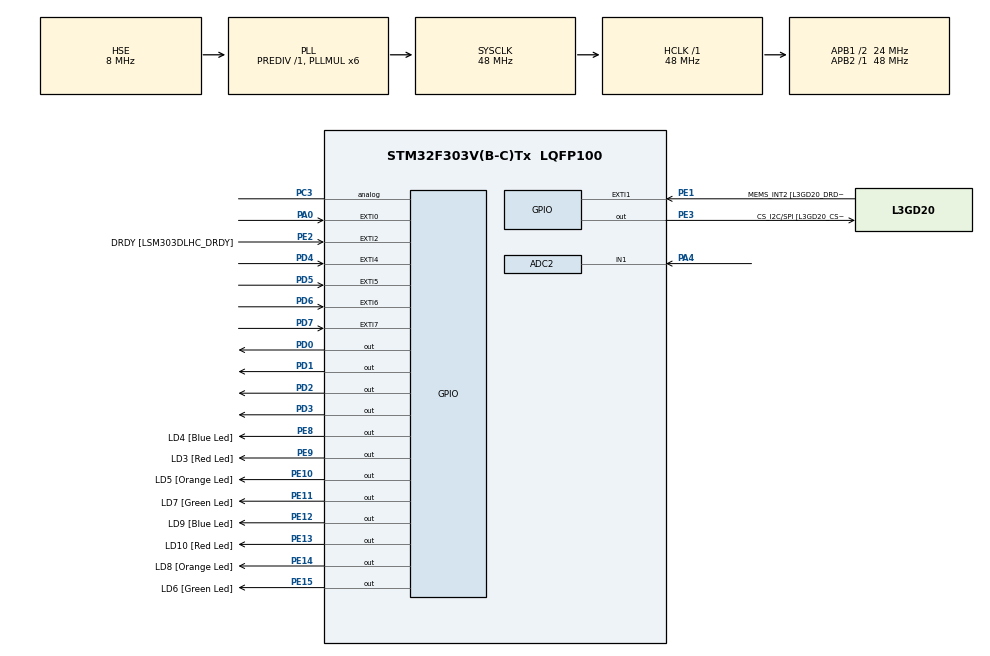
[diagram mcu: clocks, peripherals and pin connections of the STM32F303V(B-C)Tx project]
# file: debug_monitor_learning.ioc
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ADC2.Channel-0\#ChannelRegularConversion=ADC_CHANNEL_1
ADC2.NbrOfConversionFlag=1
ADC2.Offset-0\#ChannelRegularConversion=0
ADC2.OffsetNumber-0\#ChannelRegularConversion=ADC_OFFSET_NONE
ADC2.Rank-0\#ChannelRegularConversion=1
ADC2.SamplingTime-0\#ChannelRegularConversion=ADC_SAMPLETIME_601CYCLES_5
ADC2.SamplingTimeOPAMP-0\#ChannelRegularConversion=ADC_SAMPLETIME_19CYCLES_5
Mcu.Family=STM32F3
Mcu.Name=STM32F303V(B-C)Tx
Mcu.Package=LQFP100
NVIC.ADC1_2_IRQn=true\:1\:0\:true\:false\:true\:true\:true
NVIC.PriorityGroup=NVIC_PRIORITYGROUP_3
NVIC.TIM3_IRQn=true\:3\:0\:true\:false\:true\:true\:true
PA0.GPIO_ModeDefaultEXTI=GPIO_MODE_IT_RISING_FALLING
PA0.GPIO_PuPd=GPIO_PULLDOWN
PA0.Signal=GPXTI0
PA11.GPIO_Label=DM
PA11.Signal=USB_DM
PA12.GPIO_Label=DP
PA12.Signal=USB_DP
PA13.GPIO_Label=SWDIO
PA13.Mode=Serial_Wire
PA13.Signal=SYS_JTMS-SWDIO
PA14.GPIO_Label=SWCLK
PA14.Mode=Serial_Wire
PA14.Signal=SYS_JTCK-SWCLK
PA4.Mode=IN1-Single-Ended
PA4.Signal=ADC2_IN1
PB3.GPIO_Label=SWO
PB3.Signal=SYS_JTDO-TRACESWO
PB6.GPIO_Label=I2C1_SCL [LSM303DLHC_SCL]
PB6.GPIO_Pu=GPIO_PULLUP
PB6.Signal=I2C1_SCL
PB7.GPIO_Label=I2C1_SDA [LSM303DLHC_SDA]
PB7.GPIO_Pu=GPIO_PULLUP
PB7.Signal=I2C1_SDA
PC14-OSC32_IN.GPIO_Label=OSC32_IN
PC14-OSC32_IN.Signal=RCC_OSC32_IN
PC15-OSC32_OUT.GPIO_Label=OSC32_OUT
PC15-OSC32_OUT.Signal=RCC_OSC32_OUT
PC3.Signal=GPIO_Analog
PD0.Signal=GPIO_Output
PD1.Signal=GPIO_Output
PD2.Signal=GPIO_Output
PD3.Signal=GPIO_Output
PD4.GPIO_ModeDefaultEXTI=GPIO_MODE_IT_RISING
PD4.GPIO_PuPd=GPIO_PULLDOWN
PD4.Signal=GPXTI4
PD5.GPIO_ModeDefaultEXTI=GPIO_MODE_IT_RISING
PD5.GPIO_PuPd=GPIO_PULLDOWN
PD5.Signal=GPXTI5
PD6.GPIO_ModeDefaultEXTI=GPIO_MODE_IT_RISING
PD6.GPIO_PuPd=GPIO_PULLDOWN
PD6.Signal=GPXTI6
PD7.GPIO_ModeDefaultEXTI=GPIO_MODE_IT_RISING
PD7.GPIO_PuPd=GPIO_PULLDOWN
PD7.Signal=GPXTI7
PE1.GPIO_Label=MEMS_INT2 [L3GD20_DRDY/INT2]
PE1.GPIO_ModeDefaultEXTI=GPIO_MODE_EVT_RISING
PE1.Signal=GPXTI1
PE10.GPIO_Label=LD5 [Orange Led]
PE10.Signal=GPIO_Output
PE11.GPIO_Label=LD7 [Green Led]
PE11.Signal=GPIO_Output
PE12.GPIO_Label=LD9 [Blue Led]
PE12.Signal=GPIO_Output
PE13.GPIO_Label=LD10 [Red Led]
PE13.Signal=GPIO_Output
PE14.GPIO_Label=LD8 [Orange Led]
PE14.Signal=GPIO_Output
PE15.GPIO_Label=LD6 [Green Led]
PE15.Signal=GPIO_Output
PE2.GPIO_Label=DRDY [LSM303DLHC_DRDY]
PE2.GPIO_ModeDefaultEXTI=GPIO_MODE_EVT_RISING
PE2.Signal=GPXTI2
PE3.GPIO_Label=CS_I2C/SPI [L3GD20_CS_I2C/SPI]
PE3.Signal=GPIO_Output
PE8.GPIO_Label=LD4 [Blue Led]
PE8.Signal=GPIO_Output
PE9.GPIO_Label=LD3 [Red Led]
PE9.Signal=GPIO_Output
PF0-OSC_IN.GPIO_Label=OSC_IN
PF0-OSC_IN.Mode=HSE-External-Clock-Source
PF0-OSC_IN.Signal=RCC_OSC_IN
PF1-OSC_OUT.GPIO_Label=OSC_OUT
PF1-OSC_OUT.Signal=RCC_OSC_OUT
ProjectManager.HeapSize=0x200
ProjectManager.StackSize=0x400
ProjectManager.TargetToolchain=STM32CubeIDE
RCC.AHBFreq_Value=48000000
RCC.APB1CLKDivider=RCC_HCLK_DIV2
RCC.APB1Freq_Value=24000000
RCC.APB1TimFreq_Value=48000000
RCC.APB2Freq_Value=48000000
RCC.APB2TimFreq_Value=48000000
RCC.CortexFreq_Value=48000000
RCC.HCLKFreq_Value=48000000
RCC.HSE_VALUE=8000000
RCC.HSI_VALUE=8000000
RCC.LSE_VALUE=32768
RCC.PLLMUL=RCC_PLL_MUL6
RCC.PLLSourceVirtual=RCC_PLLSOURCE_HSE
RCC.SYSCLKFreq_VALUE=48000000
RCC.SYSCLKSourceVirtual=RCC_SYSCLKSOURCE_PLLCLK
RCC.USBFreq_Value=48000000
RTC.AsynchPrediv=39
RTC.Format=RTC_FORMAT_BIN
RTC.Hours=18
RTC.Minutes=30
RTC.StoreOperation=RTC_STOREOPERATION_SET
RTC.SynchPrediv=999
TIM3.Period=9999
TIM3.Prescaler=99
VP_RTC_VS_RTC_Activate.Mode=RTC_Enabled
VP_RTC_VS_RTC_Calendar.Mode=RTC_Calendar
VP_TIM3_VS_ClockSourceINT.Mode=Internal
board=STM32F3DISCOVERY

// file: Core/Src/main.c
/* USER CODE BEGIN Header */
/**
  ******************************************************************************
  * @file           : main.c
  * @brief          : Main program body
  ******************************************************************************
  * @attention
  *
  * <h2><center>&copy; Copyright (c) 2021 STMicroelectronics.
  * All rights reserved.</center></h2>
  *
  * This software component is licensed by ST under BSD 3-Clause license,
  * the "License"; You may not use this file except in compliance with the
  * License. You may obtain a copy of the License at:
  *                        opensource.org/licenses/BSD-3-Clause
  *
  ******************************************************************************
  */
/* USER CODE END Header */
#include "main.h"

ADC_HandleTypeDef hadc2;

RTC_HandleTypeDef hrtc;

TIM_HandleTypeDef htim3;

/* USER CODE BEGIN PV */
int raw_temp = 0;
int inc_var = 0;
float sin_var = 0.0;
float cos_var = 0.0;
float sqrt_var = 0.0;
float temp = 0.0;
/* USER CODE END PV */

void SystemClock_Config(void);
static void MX_GPIO_Init(void);
static void MX_RTC_Init(void);
static void MX_TIM3_Init(void);
static void MX_ADC2_Init(void);

int main(void)
{

  /* MCU Configuration--------------------------------------------------------*/

  /* Reset of all peripherals, Initializes the Flash interface and the Systick. */
  HAL_Init();

  /* Configure the system clock */
  SystemClock_Config();

  /* Initialize all configured peripherals */
  MX_GPIO_Init();
  MX_RTC_Init();
  MX_TIM3_Init();
  MX_ADC2_Init();
  /* USER CODE BEGIN 2 */
  HAL_ADC_Start_IT(&hadc2);
  HAL_TIM_Base_Start_IT(&htim3);
  /* USER CODE END 2 */

  /* Infinite loop */
  while (1)
  {

  }
}

void SystemClock_Config(void)
{
  RCC_OscInitTypeDef RCC_OscInitStruct = {0};
  RCC_ClkInitTypeDef RCC_ClkInitStruct = {0};
  RCC_PeriphCLKInitTypeDef PeriphClkInit = {0};

  /** Initializes the RCC Oscillators according to the specified parameters
  * in the RCC_OscInitTypeDef structure.
  */
  RCC_OscInitStruct.OscillatorType = RCC_OSCILLATORTYPE_LSI|RCC_OSCILLATORTYPE_HSE;
  RCC_OscInitStruct.HSEState = RCC_HSE_BYPASS;
  RCC_OscInitStruct.HSEPredivValue = RCC_HSE_PREDIV_DIV1;
  RCC_OscInitStruct.HSIState = RCC_HSI_ON;
  RCC_OscInitStruct.LSIState = RCC_LSI_ON;
  RCC_OscInitStruct.PLL.PLLState = RCC_PLL_ON;
  RCC_OscInitStruct.PLL.PLLSource = RCC_PLLSOURCE_HSE;
  RCC_OscInitStruct.PLL.PLLMUL = RCC_PLL_MUL6;
  if (HAL_RCC_OscConfig(&RCC_OscInitStruct) != HAL_OK)
  {
    Error_Handler();
  }
  /** Initializes the CPU, AHB and APB buses clocks
  */
  RCC_ClkInitStruct.ClockType = RCC_CLOCKTYPE_HCLK|RCC_CLOCKTYPE_SYSCLK
                              |RCC_CLOCKTYPE_PCLK1|RCC_CLOCKTYPE_PCLK2;
  RCC_ClkInitStruct.SYSCLKSource = RCC_SYSCLKSOURCE_PLLCLK;
  RCC_ClkInitStruct.AHBCLKDivider = RCC_SYSCLK_DIV1;
  RCC_ClkInitStruct.APB1CLKDivider = RCC_HCLK_DIV2;
  RCC_ClkInitStruct.APB2CLKDivider = RCC_HCLK_DIV1;

  if (HAL_RCC_ClockConfig(&RCC_ClkInitStruct, FLASH_LATENCY_1) != HAL_OK)
  {
    Error_Handler();
  }
  PeriphClkInit.PeriphClockSelection = RCC_PERIPHCLK_RTC|RCC_PERIPHCLK_ADC12;
  PeriphClkInit.Adc12ClockSelection = RCC_ADC12PLLCLK_DIV1;
  PeriphClkInit.RTCClockSelection = RCC_RTCCLKSOURCE_LSI;
  if (HAL_RCCEx_PeriphCLKConfig(&PeriphClkInit) != HAL_OK)
  {
    Error_Handler();
  }
}

static void MX_ADC2_Init(void)
{

  ADC_ChannelConfTypeDef sConfig = {0};

  /** Common config
  */
  hadc2.Instance = ADC2;
  hadc2.Init.ClockPrescaler = ADC_CLOCK_ASYNC_DIV1;
  hadc2.Init.Resolution = ADC_RESOLUTION_12B;
  hadc2.Init.ScanConvMode = ADC_SCAN_DISABLE;
  hadc2.Init.ContinuousConvMode = DISABLE;
  hadc2.Init.DiscontinuousConvMode = DISABLE;
  hadc2.Init.ExternalTrigConvEdge = ADC_EXTERNALTRIGCONVEDGE_NONE;
  hadc2.Init.ExternalTrigConv = ADC_SOFTWARE_START;
  hadc2.Init.DataAlign = ADC_DATAALIGN_RIGHT;
  hadc2.Init.NbrOfConversion = 1;
  hadc2.Init.DMAContinuousRequests = DISABLE;
  hadc2.Init.EOCSelection = ADC_EOC_SINGLE_CONV;
  hadc2.Init.LowPowerAutoWait = DISABLE;
  hadc2.Init.Overrun = ADC_OVR_DATA_OVERWRITTEN;
  if (HAL_ADC_Init(&hadc2) != HAL_OK)
  {
    Error_Handler();
  }
  /** Configure Regular Channel
  */
  sConfig.Channel = ADC_CHANNEL_1;
  sConfig.Rank = ADC_REGULAR_RANK_1;
  sConfig.SingleDiff = ADC_SINGLE_ENDED;
  sConfig.SamplingTime = ADC_SAMPLETIME_601CYCLES_5;
  sConfig.OffsetNumber = ADC_OFFSET_NONE;
  sConfig.Offset = 0;
  if (HAL_ADC_ConfigChannel(&hadc2, &sConfig) != HAL_OK)
  {
    Error_Handler();
  }

}

static void MX_RTC_Init(void)
{

  RTC_TimeTypeDef sTime = {0};
  RTC_DateTypeDef sDate = {0};

  /** Initialize RTC Only
  */
  hrtc.Instance = RTC;
  hrtc.Init.HourFormat = RTC_HOURFORMAT_24;
  hrtc.Init.AsynchPrediv = 39;
  hrtc.Init.SynchPrediv = 999;
  hrtc.Init.OutPut = RTC_OUTPUT_DISABLE;
  hrtc.Init.OutPutPolarity = RTC_OUTPUT_POLARITY_HIGH;
  hrtc.Init.OutPutType = RTC_OUTPUT_TYPE_OPENDRAIN;
  if (HAL_RTC_Init(&hrtc) != HAL_OK)
  {
    Error_Handler();
  }

  /** Initialize RTC and set the Time and Date
  */
  sTime.Hours = 18;
  sTime.Minutes = 30;
  sTime.Seconds = 0;
  sTime.DayLightSaving = RTC_DAYLIGHTSAVING_NONE;
  sTime.StoreOperation = RTC_STOREOPERATION_SET;
  if (HAL_RTC_SetTime(&hrtc, &sTime, RTC_FORMAT_BIN) != HAL_OK)
  {
    Error_Handler();
  }
  sDate.WeekDay = RTC_WEEKDAY_MONDAY;
  sDate.Month = RTC_MONTH_JANUARY;
  sDate.Date = 1;
  sDate.Year = 0;

  if (HAL_RTC_SetDate(&hrtc, &sDate, RTC_FORMAT_BIN) != HAL_OK)
  {
    Error_Handler();
  }

}

static void MX_TIM3_Init(void)
{

  TIM_ClockConfigTypeDef sClockSourceConfig = {0};
  TIM_MasterConfigTypeDef sMasterConfig = {0};

  htim3.Instance = TIM3;
  htim3.Init.Prescaler = 99;
  htim3.Init.CounterMode = TIM_COUNTERMODE_UP;
  htim3.Init.Period = 9999;
  htim3.Init.ClockDivision = TIM_CLOCKDIVISION_DIV1;
  htim3.Init.AutoReloadPreload = TIM_AUTORELOAD_PRELOAD_DISABLE;
  if (HAL_TIM_Base_Init(&htim3) != HAL_OK)
  {
    Error_Handler();
  }
  sClockSourceConfig.ClockSource = TIM_CLOCKSOURCE_INTERNAL;
  if (HAL_TIM_ConfigClockSource(&htim3, &sClockSourceConfig) != HAL_OK)
  {
    Error_Handler();
  }
  sMasterConfig.MasterOutputTrigger = TIM_TRGO_RESET;
  sMasterConfig.MasterSlaveMode = TIM_MASTERSLAVEMODE_DISABLE;
  if (HAL_TIMEx_MasterConfigSynchronization(&htim3, &sMasterConfig) != HAL_OK)
  {
    Error_Handler();
  }

}

static void MX_GPIO_Init(void)
{
  GPIO_InitTypeDef GPIO_InitStruct = {0};

  /* GPIO Ports Clock Enable */
  __HAL_RCC_GPIOE_CLK_ENABLE();
  __HAL_RCC_GPIOC_CLK_ENABLE();
  __HAL_RCC_GPIOF_CLK_ENABLE();
  __HAL_RCC_GPIOA_CLK_ENABLE();
  __HAL_RCC_GPIOD_CLK_ENABLE();
  __HAL_RCC_GPIOB_CLK_ENABLE();

  /*Configure GPIO pin Output Level */
  HAL_GPIO_WritePin(GPIOE, CS_I2C_SPI_Pin|LD4_Pin|LD3_Pin|LD5_Pin
                          |LD7_Pin|LD9_Pin|LD10_Pin|LD8_Pin
                          |LD6_Pin, GPIO_PIN_RESET);

  /*Configure GPIO pin Output Level */
  HAL_GPIO_WritePin(GPIOD, GPIO_PIN_0|GPIO_PIN_1|GPIO_PIN_2|GPIO_PIN_3, GPIO_PIN_RESET);

  /*Configure GPIO pins : DRDY_Pin MEMS_INT2_Pin */
  GPIO_InitStruct.Pin = DRDY_Pin|MEMS_INT2_Pin;
  GPIO_InitStruct.Mode = GPIO_MODE_EVT_RISING;
  GPIO_InitStruct.Pull = GPIO_NOPULL;
  HAL_GPIO_Init(GPIOE, &GPIO_InitStruct);

  /*Configure GPIO pins : CS_I2C_SPI_Pin LD4_Pin LD3_Pin LD5_Pin
                           LD7_Pin LD9_Pin LD10_Pin LD8_Pin
                           LD6_Pin */
  GPIO_InitStruct.Pin = CS_I2C_SPI_Pin|LD4_Pin|LD3_Pin|LD5_Pin
                          |LD7_Pin|LD9_Pin|LD10_Pin|LD8_Pin
                          |LD6_Pin;
  GPIO_InitStruct.Mode = GPIO_MODE_OUTPUT_PP;
  GPIO_InitStruct.Pull = GPIO_NOPULL;
  GPIO_InitStruct.Speed = GPIO_SPEED_FREQ_LOW;
  HAL_GPIO_Init(GPIOE, &GPIO_InitStruct);

  /*Configure GPIO pin : PC3 */
  GPIO_InitStruct.Pin = GPIO_PIN_3;
  GPIO_InitStruct.Mode = GPIO_MODE_ANALOG;
  GPIO_InitStruct.Pull = GPIO_NOPULL;
  HAL_GPIO_Init(GPIOC, &GPIO_InitStruct);

  /*Configure GPIO pin : PA0 */
  GPIO_InitStruct.Pin = GPIO_PIN_0;
  GPIO_InitStruct.Mode = GPIO_MODE_IT_RISING_FALLING;
  GPIO_InitStruct.Pull = GPIO_PULLDOWN;
  HAL_GPIO_Init(GPIOA, &GPIO_InitStruct);

  /*Configure GPIO pins : DM_Pin DP_Pin */
  GPIO_InitStruct.Pin = DM_Pin|DP_Pin;
  GPIO_InitStruct.Mode = GPIO_MODE_AF_PP;
  GPIO_InitStruct.Pull = GPIO_NOPULL;
  GPIO_InitStruct.Speed = GPIO_SPEED_FREQ_HIGH;
  GPIO_InitStruct.Alternate = GPIO_AF14_USB;
  HAL_GPIO_Init(GPIOA, &GPIO_InitStruct);

  /*Configure GPIO pins : PD0 PD1 PD2 PD3 */
  GPIO_InitStruct.Pin = GPIO_PIN_0|GPIO_PIN_1|GPIO_PIN_2|GPIO_PIN_3;
  GPIO_InitStruct.Mode = GPIO_MODE_OUTPUT_PP;
  GPIO_InitStruct.Pull = GPIO_NOPULL;
  GPIO_InitStruct.Speed = GPIO_SPEED_FREQ_LOW;
  HAL_GPIO_Init(GPIOD, &GPIO_InitStruct);

  /*Configure GPIO pins : PD4 PD5 PD6 PD7 */
  GPIO_InitStruct.Pin = GPIO_PIN_4|GPIO_PIN_5|GPIO_PIN_6|GPIO_PIN_7;
  GPIO_InitStruct.Mode = GPIO_MODE_IT_RISING;
  GPIO_InitStruct.Pull = GPIO_PULLDOWN;
  HAL_GPIO_Init(GPIOD, &GPIO_InitStruct);

  /*Configure GPIO pins : I2C1_SCL_Pin I2C1_SDA_Pin */
  GPIO_InitStruct.Pin = I2C1_SCL_Pin|I2C1_SDA_Pin;
  GPIO_InitStruct.Mode = GPIO_MODE_AF_OD;
  GPIO_InitStruct.Pull = GPIO_PULLUP;
  GPIO_InitStruct.Speed = GPIO_SPEED_FREQ_HIGH;
  GPIO_InitStruct.Alternate = GPIO_AF4_I2C1;
  HAL_GPIO_Init(GPIOB, &GPIO_InitStruct);

}

void Error_Handler(void)
{
  __disable_irq();
  while (1)
  {
  }
}

/************************ (C) COPYRIGHT STMicroelectronics *****END OF FILE****/
